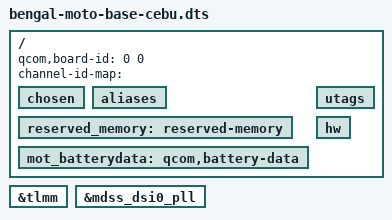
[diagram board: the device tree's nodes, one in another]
/* Copyright (c) 2020, The Linux Foundation. All rights reserved.
 *
 * This program is free software; you can redistribute it and/or modify
 * it under the terms of the GNU General Public License version 2 and
 * only version 2 as published by the Free Software Foundation.
 *
 * This program is distributed in the hope that it will be useful,
 * but WITHOUT ANY WARRANTY; without even the implied warranty of
 * MERCHANTABILITY or FITNESS FOR A PARTICULAR PURPOSE.  See the
 * GNU General Public License for more details.
 */

/dts-v1/;

#include "bengal-moto-base.dtsi"

/ {
	qcom,board-id = <0 0>;
	channel-id-map = "";
/*
 * Some nodes need labels assigned to appear in __symbols__
 */
	chosen: chosen { };
	aliases: aliases { };
	reserved_memory: reserved-memory { };
	mot_batterydata: qcom,battery-data { };
	utags: utags { };
	hw: hw { };
};

&tlmm {
	/* delete cam_sensor_csi_mux_oe & cam_sensor_csi_mux_sel which are uselsess in Cebu. */
        /* cam_sensor_csi_mux_oe & cam_sensor_csi_mux_sel default gpio66/67 are conflict with TP rst/int gpio. */
	/delete-node/ cam_sensor_csi_mux_oe_active;
	/delete-node/ cam_sensor_csi_mux_oe_suspend;
        /delete-node/ cam_sensor_csi_mux_sel_active;
        /delete-node/ cam_sensor_csi_mux_sel_suspend;
};

&mdss_dsi0_pll {
	/delete-property/ qcom,dsi-pll-ssc-en;
};
